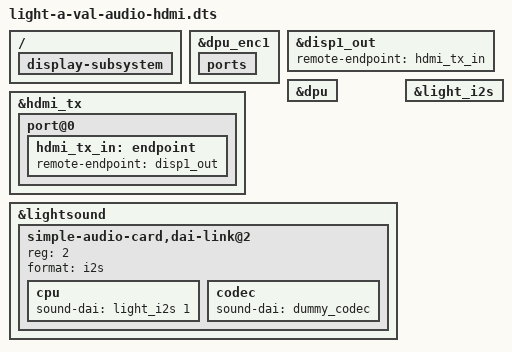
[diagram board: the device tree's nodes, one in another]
/* SPDX-License-Identifier: GPL-2.0 */
/*
 * Copyright (C) 2021 Alibaba Group Holding Limited.
 */

/dts-v1/;

#include "light-a-val-audio.dts"

/ {
	display-subsystem {
		status = "okay";
	};
};

&dpu_enc1 {
	ports {
		/delete-node/ port@0;
	};
};

&disp1_out {
	remote-endpoint = <&hdmi_tx_in>;
};

&dpu {
	status = "okay";
};

&hdmi_tx {
	status = "okay";

	port@0 {
		/* input */
		hdmi_tx_in: endpoint {
			remote-endpoint = <&disp1_out>;
		};
	};
};

&lightsound {
	status = "okay";
	
	simple-audio-card,dai-link@2 {          /* I2S - HDMI */
		reg = <2>;
		format = "i2s";
		cpu {
			sound-dai = <&light_i2s 1>;
		};
		codec {
			sound-dai = <&dummy_codec>;
		};
	};
};

&light_i2s {
        status = "okay";
};
